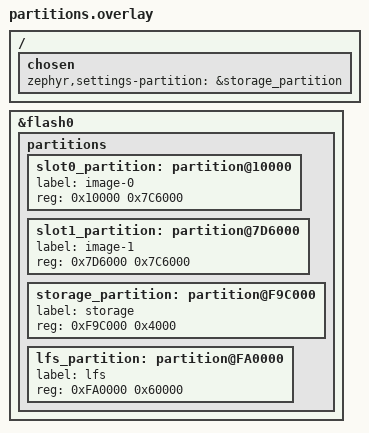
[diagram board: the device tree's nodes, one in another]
/* 16 MB MCUboot layout shared by the application and MCUboot. */
/delete-node/ &sys_partition;
/delete-node/ &slot0_lpcore_partition;
/delete-node/ &slot1_lpcore_partition;
/delete-node/ &storage_partition;
/delete-node/ &scratch_partition;
/delete-node/ &coredump_partition;
/delete-node/ &slot0_partition;
/delete-node/ &slot1_partition;

/ {
	chosen {
		zephyr,settings-partition = &storage_partition;
	};
};

&flash0 {
	partitions {
		slot0_partition: partition@10000 {
			label = "image-0";
			reg = <0x10000 0x7C6000>;
		};
		slot1_partition: partition@7D6000 {
			label = "image-1";
			reg = <0x7D6000 0x7C6000>;
		};
		storage_partition: partition@F9C000 {
			label = "storage";
			reg = <0xF9C000 0x4000>;
		};
		lfs_partition: partition@FA0000 {
			label = "lfs";
			reg = <0xFA0000 0x60000>;
		};
	};
};
